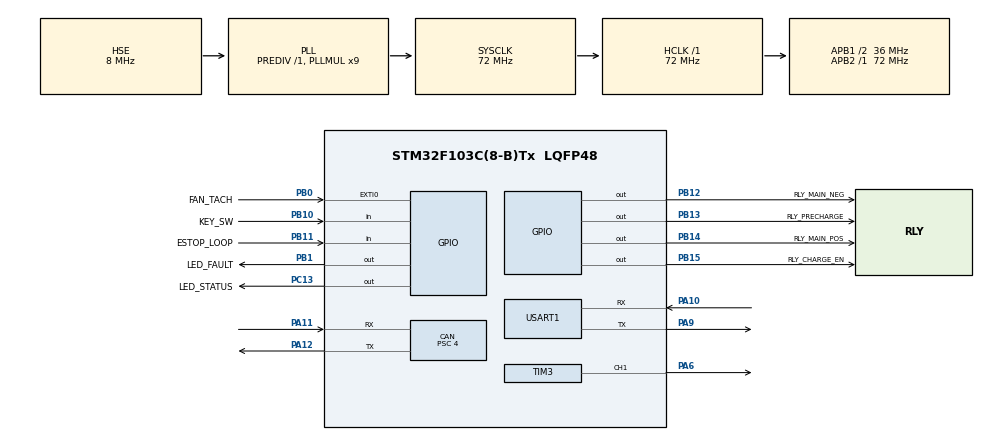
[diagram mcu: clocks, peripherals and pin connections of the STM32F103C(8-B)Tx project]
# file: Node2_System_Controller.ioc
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CAN.ABOM=ENABLE
CAN.BS1=CAN_BS1_14TQ
CAN.BS2=CAN_BS2_3TQ
CAN.CalculateBaudRate=500000
CAN.CalculateTimeBit=2000
CAN.CalculateTimeQuantum=111.11111111111111
CAN.NART=ENABLE
CAN.Prescaler=4
CAN.SJW=CAN_SJW_2TQ
CAN.TXFP=ENABLE
IWDG.Prescaler=IWDG_PRESCALER_64
IWDG.Reload=1250
Mcu.Family=STM32F1
Mcu.Name=STM32F103C(8-B)Tx
Mcu.Package=LQFP48
NVIC.CAN1_SCE_IRQn=true\:6\:0\:false\:false\:true\:true\:true\:true
NVIC.EXTI0_IRQn=true\:8\:0\:false\:false\:true\:true\:true\:true
NVIC.PriorityGroup=NVIC_PRIORITYGROUP_4
NVIC.USART1_IRQn=true\:10\:0\:false\:false\:true\:true\:true\:true
NVIC.USB_HP_CAN1_TX_IRQn=true\:6\:0\:false\:false\:true\:true\:true\:true
NVIC.USB_LP_CAN1_RX0_IRQn=true\:6\:0\:false\:false\:true\:true\:true\:true
PA10.Mode=Asynchronous
PA10.Signal=USART1_RX
PA11.Mode=CAN_Activate
PA11.Signal=CAN_RX
PA12.Mode=CAN_Activate
PA12.Signal=CAN_TX
PA13.Mode=Serial_Wire
PA13.Signal=SYS_JTMS-SWDIO
PA14.Mode=Serial_Wire
PA14.Signal=SYS_JTCK-SWCLK
PA6.Signal=S_TIM3_CH1
PA9.Mode=Asynchronous
PA9.Signal=USART1_TX
PB0.GPIO_Label=FAN_TACH
PB0.GPIO_ModeDefaultEXTI=GPIO_MODE_IT_FALLING
PB0.GPIO_PuPd=GPIO_PULLUP
PB0.Signal=GPXTI0
PB1.GPIO_Label=LED_FAULT
PB1.Signal=GPIO_Output
PB10.GPIO_Label=KEY_SW
PB10.GPIO_PuPd=GPIO_PULLUP
PB10.Signal=GPIO_Input
PB11.GPIO_Label=ESTOP_LOOP
PB11.GPIO_PuPd=GPIO_PULLUP
PB11.Signal=GPIO_Input
PB12.GPIO_Label=RLY_MAIN_NEG
PB12.Signal=GPIO_Output
PB13.GPIO_Label=RLY_PRECHARGE
PB13.Signal=GPIO_Output
PB14.GPIO_Label=RLY_MAIN_POS
PB14.Signal=GPIO_Output
PB15.GPIO_Label=RLY_CHARGE_EN
PB15.Signal=GPIO_Output
PC13-TAMPER-RTC.GPIO_Label=LED_STATUS
PC13-TAMPER-RTC.PinState=GPIO_PIN_SET
PC13-TAMPER-RTC.Signal=GPIO_Output
PD0-OSC_IN.Mode=HSE-External-Oscillator
PD0-OSC_IN.Signal=RCC_OSC_IN
PD1-OSC_OUT.Mode=HSE-External-Oscillator
PD1-OSC_OUT.Signal=RCC_OSC_OUT
ProjectManager.HeapSize=0x200
ProjectManager.StackSize=0x800
ProjectManager.TargetToolchain=CMake
RCC.ADCPresc=RCC_ADCPCLK2_DIV2
RCC.AHBFreq_Value=72000000
RCC.APB1CLKDivider=RCC_HCLK_DIV2
RCC.APB1Freq_Value=36000000
RCC.APB1TimFreq_Value=72000000
RCC.APB2Freq_Value=72000000
RCC.APB2TimFreq_Value=72000000
RCC.HCLKFreq_Value=72000000
RCC.PLLMUL=RCC_PLL_MUL9
RCC.PLLSourceVirtual=RCC_PLLSOURCE_HSE
RCC.SYSCLKFreq_VALUE=72000000
RCC.SYSCLKSource=RCC_SYSCLKSOURCE_PLLCLK
RCC.USBFreq_Value=72000000
SH.S_TIM3_CH1.0=TIM3_CH1,PWM Generation1 CH1
TIM3.Channel-PWM\ Generation1\ CH1=TIM_CHANNEL_1
TIM3.Period=2879
TIM3.Prescaler=0
USART1.VirtualMode=VM_ASYNC
VP_IWDG_VS_IWDG.Mode=IWDG_Activate
board=custom

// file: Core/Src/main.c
/* USER CODE BEGIN Header */
/**
  ******************************************************************************
  * @file           : main.c
  * @brief          : Distributed BMS - Node 2 System Controller
  *                   STM32F103C8T6 (Blue Pill): precharge + main contactors,
  *                   charge enable, PWM cooling fan, isolated CAN (ISO1042)
  *
  *  Peripheral set-up is generated by STM32CubeMX (Node2_System_Controller.ioc).
  *  All application code lives in App/ and is called from the USER CODE
  *  sections below, so the project can be regenerated safely.
  ******************************************************************************
  */
/* USER CODE END Header */
#include "main.h"

/* USER CODE BEGIN Includes */
#include "ctrl_app.h"
#include "ctrl_io.h"
/* USER CODE END Includes */

CAN_HandleTypeDef hcan;

IWDG_HandleTypeDef hiwdg;

TIM_HandleTypeDef htim3;

UART_HandleTypeDef huart1;

void SystemClock_Config(void);
static void MX_GPIO_Init(void);
static void MX_CAN_Init(void);
static void MX_TIM3_Init(void);
static void MX_USART1_UART_Init(void);
static void MX_IWDG_Init(void);

int main(void)
{

  /* MCU Configuration--------------------------------------------------------*/

  /* Reset of all peripherals, Initializes the Flash interface and the Systick. */
  HAL_Init();

  /* Configure the system clock */
  SystemClock_Config();

  /* Initialize all configured peripherals */
  MX_GPIO_Init();
  MX_CAN_Init();
  MX_TIM3_Init();
  MX_USART1_UART_Init();
  /* USER CODE BEGIN 2 */
  Ctrl_App_Init(&hcan, &htim3, &huart1, &hiwdg);
#if (CTRL_USE_IWDG == 1)
  MX_IWDG_Init();
#endif
  /* USER CODE END 2 */

  /* Infinite loop */
  while (1)
  {

    /* USER CODE BEGIN 3 */
    Ctrl_App_Loop();
  }
  /* USER CODE END 3 */
}

void SystemClock_Config(void)
{
  RCC_OscInitTypeDef RCC_OscInitStruct = {0};
  RCC_ClkInitTypeDef RCC_ClkInitStruct = {0};

  /** Initializes the RCC Oscillators according to the specified parameters
  * in the RCC_OscInitTypeDef structure.
  */
  RCC_OscInitStruct.OscillatorType = RCC_OSCILLATORTYPE_LSI|RCC_OSCILLATORTYPE_HSE;
  RCC_OscInitStruct.HSEState = RCC_HSE_ON;
  RCC_OscInitStruct.HSEPredivValue = RCC_HSE_PREDIV_DIV1;
  RCC_OscInitStruct.HSIState = RCC_HSI_ON;
  RCC_OscInitStruct.LSIState = RCC_LSI_ON;
  RCC_OscInitStruct.PLL.PLLState = RCC_PLL_ON;
  RCC_OscInitStruct.PLL.PLLSource = RCC_PLLSOURCE_HSE;
  RCC_OscInitStruct.PLL.PLLMUL = RCC_PLL_MUL9;
  if (HAL_RCC_OscConfig(&RCC_OscInitStruct) != HAL_OK)
  {
    Error_Handler();
  }

  /** Initializes the CPU, AHB and APB buses clocks
  */
  RCC_ClkInitStruct.ClockType = RCC_CLOCKTYPE_HCLK|RCC_CLOCKTYPE_SYSCLK
                              |RCC_CLOCKTYPE_PCLK1|RCC_CLOCKTYPE_PCLK2;
  RCC_ClkInitStruct.SYSCLKSource = RCC_SYSCLKSOURCE_PLLCLK;
  RCC_ClkInitStruct.AHBCLKDivider = RCC_SYSCLK_DIV1;
  RCC_ClkInitStruct.APB1CLKDivider = RCC_HCLK_DIV2;
  RCC_ClkInitStruct.APB2CLKDivider = RCC_HCLK_DIV1;

  if (HAL_RCC_ClockConfig(&RCC_ClkInitStruct, FLASH_LATENCY_2) != HAL_OK)
  {
    Error_Handler();
  }
}

static void MX_CAN_Init(void)
{

  hcan.Instance = CAN1;
  hcan.Init.Prescaler = 4;
  hcan.Init.Mode = CAN_MODE_NORMAL;
  hcan.Init.SyncJumpWidth = CAN_SJW_2TQ;
  hcan.Init.TimeSeg1 = CAN_BS1_14TQ;
  hcan.Init.TimeSeg2 = CAN_BS2_3TQ;
  hcan.Init.TimeTriggeredMode = DISABLE;
  hcan.Init.AutoBusOff = ENABLE;
  hcan.Init.AutoWakeUp = DISABLE;
  hcan.Init.AutoRetransmission = ENABLE;
  hcan.Init.ReceiveFifoLocked = DISABLE;
  hcan.Init.TransmitFifoPriority = ENABLE;
  if (HAL_CAN_Init(&hcan) != HAL_OK)
  {
    Error_Handler();
  }

}

static void MX_IWDG_Init(void)
{

  hiwdg.Instance = IWDG;
  hiwdg.Init.Prescaler = IWDG_PRESCALER_64;
  hiwdg.Init.Reload = 1250;
  if (HAL_IWDG_Init(&hiwdg) != HAL_OK)
  {
    Error_Handler();
  }

}

static void MX_TIM3_Init(void)
{

  TIM_MasterConfigTypeDef sMasterConfig = {0};
  TIM_OC_InitTypeDef sConfigOC = {0};

  htim3.Instance = TIM3;
  htim3.Init.Prescaler = 0;
  htim3.Init.CounterMode = TIM_COUNTERMODE_UP;
  htim3.Init.Period = 2879;
  htim3.Init.ClockDivision = TIM_CLOCKDIVISION_DIV1;
  htim3.Init.AutoReloadPreload = TIM_AUTORELOAD_PRELOAD_DISABLE;
  if (HAL_TIM_PWM_Init(&htim3) != HAL_OK)
  {
    Error_Handler();
  }
  sMasterConfig.MasterOutputTrigger = TIM_TRGO_RESET;
  sMasterConfig.MasterSlaveMode = TIM_MASTERSLAVEMODE_DISABLE;
  if (HAL_TIMEx_MasterConfigSynchronization(&htim3, &sMasterConfig) != HAL_OK)
  {
    Error_Handler();
  }
  sConfigOC.OCMode = TIM_OCMODE_PWM1;
  sConfigOC.Pulse = 0;
  sConfigOC.OCPolarity = TIM_OCPOLARITY_HIGH;
  sConfigOC.OCFastMode = TIM_OCFAST_DISABLE;
  if (HAL_TIM_PWM_ConfigChannel(&htim3, &sConfigOC, TIM_CHANNEL_1) != HAL_OK)
  {
    Error_Handler();
  }
  HAL_TIM_MspPostInit(&htim3);

}

static void MX_USART1_UART_Init(void)
{

  huart1.Instance = USART1;
  huart1.Init.BaudRate = 115200;
  huart1.Init.WordLength = UART_WORDLENGTH_8B;
  huart1.Init.StopBits = UART_STOPBITS_1;
  huart1.Init.Parity = UART_PARITY_NONE;
  huart1.Init.Mode = UART_MODE_TX_RX;
  huart1.Init.HwFlowCtl = UART_HWCONTROL_NONE;
  huart1.Init.OverSampling = UART_OVERSAMPLING_16;
  if (HAL_UART_Init(&huart1) != HAL_OK)
  {
    Error_Handler();
  }

}

static void MX_GPIO_Init(void)
{
  GPIO_InitTypeDef GPIO_InitStruct = {0};

  /* GPIO Ports Clock Enable */
  __HAL_RCC_GPIOC_CLK_ENABLE();
  __HAL_RCC_GPIOD_CLK_ENABLE();
  __HAL_RCC_GPIOA_CLK_ENABLE();
  __HAL_RCC_GPIOB_CLK_ENABLE();

  /*Configure GPIO pin Output Level */
  HAL_GPIO_WritePin(LED_STATUS_GPIO_Port, LED_STATUS_Pin, GPIO_PIN_SET);

  /*Configure GPIO pin Output Level */
  HAL_GPIO_WritePin(GPIOB, LED_FAULT_Pin|RLY_MAIN_NEG_Pin|RLY_PRECHARGE_Pin|RLY_MAIN_POS_Pin
                          |RLY_CHARGE_EN_Pin, GPIO_PIN_RESET);

  /*Configure GPIO pin : LED_STATUS_Pin */
  GPIO_InitStruct.Pin = LED_STATUS_Pin;
  GPIO_InitStruct.Mode = GPIO_MODE_OUTPUT_PP;
  GPIO_InitStruct.Pull = GPIO_NOPULL;
  GPIO_InitStruct.Speed = GPIO_SPEED_FREQ_LOW;
  HAL_GPIO_Init(LED_STATUS_GPIO_Port, &GPIO_InitStruct);

  /*Configure GPIO pin : FAN_TACH_Pin */
  GPIO_InitStruct.Pin = FAN_TACH_Pin;
  GPIO_InitStruct.Mode = GPIO_MODE_IT_FALLING;
  GPIO_InitStruct.Pull = GPIO_PULLUP;
  HAL_GPIO_Init(FAN_TACH_GPIO_Port, &GPIO_InitStruct);

  /*Configure GPIO pins : LED_FAULT_Pin RLY_MAIN_NEG_Pin RLY_PRECHARGE_Pin RLY_MAIN_POS_Pin
                           RLY_CHARGE_EN_Pin */
  GPIO_InitStruct.Pin = LED_FAULT_Pin|RLY_MAIN_NEG_Pin|RLY_PRECHARGE_Pin|RLY_MAIN_POS_Pin
                          |RLY_CHARGE_EN_Pin;
  GPIO_InitStruct.Mode = GPIO_MODE_OUTPUT_PP;
  GPIO_InitStruct.Pull = GPIO_NOPULL;
  GPIO_InitStruct.Speed = GPIO_SPEED_FREQ_LOW;
  HAL_GPIO_Init(GPIOB, &GPIO_InitStruct);

  /*Configure GPIO pins : KEY_SW_Pin ESTOP_LOOP_Pin */
  GPIO_InitStruct.Pin = KEY_SW_Pin|ESTOP_LOOP_Pin;
  GPIO_InitStruct.Mode = GPIO_MODE_INPUT;
  GPIO_InitStruct.Pull = GPIO_PULLUP;
  HAL_GPIO_Init(GPIOB, &GPIO_InitStruct);

  /* EXTI interrupt init*/
  HAL_NVIC_SetPriority(EXTI0_IRQn, 8, 0);
  HAL_NVIC_EnableIRQ(EXTI0_IRQn);

}

/* USER CODE BEGIN 4 */

void HAL_GPIO_EXTI_Callback(uint16_t GPIO_Pin)
{
  if (GPIO_Pin == FAN_TACH_Pin)
  {
    Io_OnTachPulse();
  }
}

/* USER CODE END 4 */

void Error_Handler(void)
{
  /* USER CODE BEGIN Error_Handler_Debug */
  /* Init failure: force every relay open, then stop. Node 1 and the
   * gateway see CTRL_STATUS disappear. */
  __disable_irq();
  Io_SetOutputs(0);
  while (1)
  {
  }
  /* USER CODE END Error_Handler_Debug */
}
